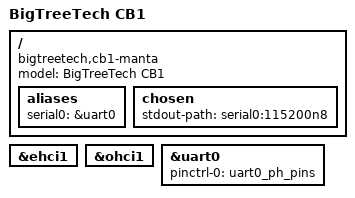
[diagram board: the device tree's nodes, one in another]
// SPDX-License-Identifier: (GPL-2.0+ or MIT)
/*
 * Copyright (C) 2023 Martin Botka <martin.botka@somainline.org>.
 */

/dts-v1/;

#include "sun50i-h616-bigtreetech-cb1.dtsi"

/ {
	model = "BigTreeTech CB1";
	compatible = "bigtreetech,cb1-manta", "bigtreetech,cb1", "allwinner,sun50i-h616";

	aliases {
		serial0 = &uart0;
	};

	chosen {
		stdout-path = "serial0:115200n8";
	};
};

&ehci1 {
	status = "okay";
};

&ohci1 {
	status = "okay";
};

&uart0 {
	pinctrl-names = "default";
	pinctrl-0 = <&uart0_ph_pins>;
	status = "okay";
};
